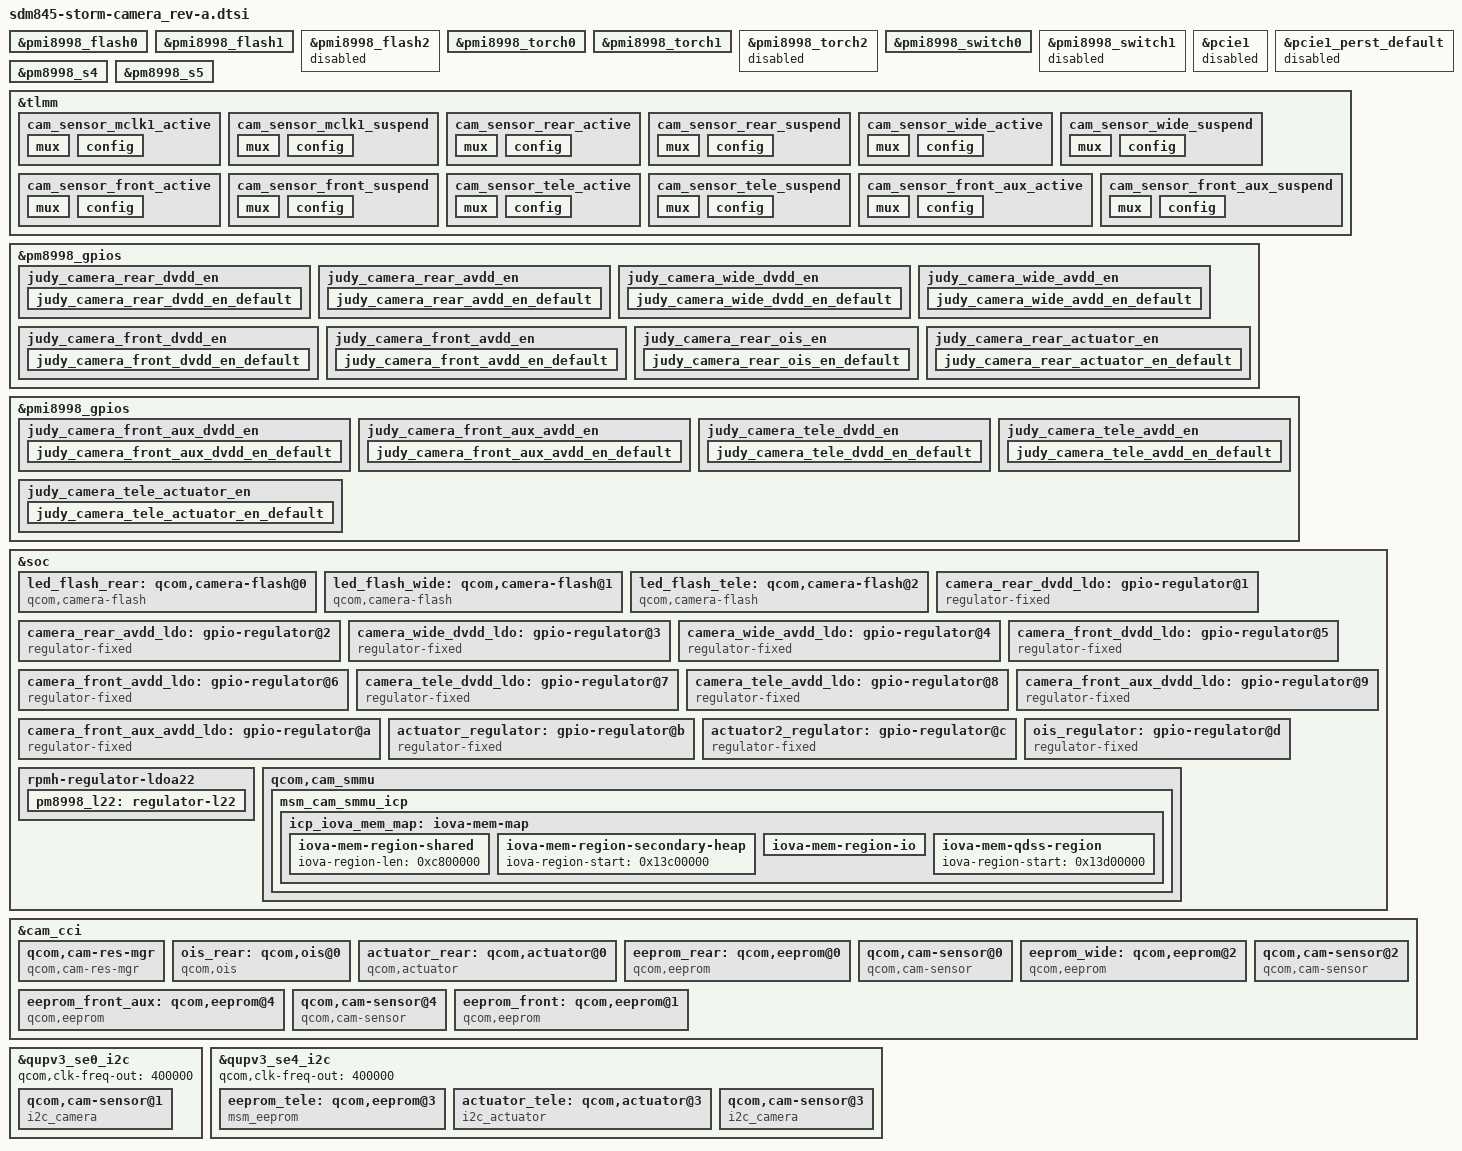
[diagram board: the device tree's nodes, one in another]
/*
 * Copyright (c) 2017 The Linux Foundation. All rights reserved.
 *
 * This program is free software; you can redistribute it and/or modify
 * it under the terms of the GNU General Public License version 2 and
 * only version 2 as published by the Free Software Foundation.
 *
 * This program is distributed in the hope that it will be useful,
 * but WITHOUT ANY WARRANTY; without even the implied warranty of
 * MERCHANTABILITY or FITNESS FOR A PARTICULAR PURPOSE.  See the
 * GNU General Public License for more details.
 */

&pmi8998_flash0 {
	status = "ok";
	qcom,max-current = <850>;
	qcom,current-ma = <850>;
	qcom,duration-ms = <500>;
};

&pmi8998_flash1 {
	status = "ok";
	qcom,max-current = <850>;
	qcom,current-ma = <850>;
	qcom,duration-ms = <500>;
};

&pmi8998_flash2 {
	status = "disabled";
};

&pmi8998_torch0 {
	status = "ok";
	qcom,max-current = <100>;
	qcom,current-ma = <100>;
};

&pmi8998_torch1 {
	status = "ok";
	qcom,max-current = <100>;
	qcom,current-ma = <100>;
};

&pmi8998_torch2 {
	status = "disabled";
};

&pmi8998_switch0 {
	status = "ok";
};

&pmi8998_switch1 {
	status = "disbled";
};

&pcie1 {
    status = "disabled";
};
&pcie1_perst_default {
    status = "disabled";
};

&pm8998_s4 {
	regulator-min-microvolt = <1800000>;
	regulator-max-microvolt = <1800000>;
	qcom,init-voltage = <1800000>;
};

&pm8998_s5 {
	regulator-min-microvolt = <2040000>;
	regulator-max-microvolt = <2040000>;
	qcom,init-voltage = <2040000>;
};

&tlmm{
        cam_sensor_mclk1_active: cam_sensor_mclk1_active {
            /* MCLK1 */
            mux {
                pins = "gpio14";
                function = "cam_mclk";
            };

            config {
                pins = "gpio14";
                bias-disable; /* No PULL */
                drive-strength = <2>; /* 2 MA */
            };
        };

        cam_sensor_mclk1_suspend: cam_sensor_mclk1_suspend {
            /* MCLK1 */
            mux {
                pins = "gpio14";
                function = "cam_mclk";
            };

            config {
                pins = "gpio14";
                bias-pull-down; /* PULL DOWN */
                drive-strength = <2>; /* 2 MA */
            };
        };

	cam_sensor_rear_active: cam_sensor_rear_active {
		/* RESET, AVDD LDO */
		mux {
			pins = "gpio84";
			function = "gpio";
		};

		config {
			pins = "gpio84";
			bias-disable; /* No PULL */
			drive-strength = <2>; /* 2 MA */
		};
	};

	cam_sensor_rear_suspend: cam_sensor_rear_suspend {
		/* RESET, AVDD LDO */
		mux {
			pins = "gpio84";
			function = "gpio";
		};

		config {
			pins = "gpio84";
			bias-pull-down; /* PULL DOWN */
			drive-strength = <2>; /* 2 MA */
			output-low;
		};
	};

	cam_sensor_wide_active: cam_sensor_wide_active {
		/* RESET, AVDD LDO */
		mux {
			pins = "gpio80", "gpio108", "gpio133", "gpio39";
			function = "gpio";
		};

		config {
			pins = "gpio80", "gpio108", "gpio133", "gpio39";
			bias-disable; /* No PULL */
			drive-strength = <2>; /* 2 MA */
		};
	};

	cam_sensor_wide_suspend: cam_sensor_wide_suspend {
		/* RESET, AVDD LDO */
		mux {
			pins = "gpio80", "gpio108", "gpio133", "gpio39";
			function = "gpio";
		};

		config {
			pins = "gpio80", "gpio108", "gpio133", "gpio39";
			bias-pull-down; /* PULL DOWN */
			drive-strength = <2>; /* 2 MA */
			output-low;
		};
	};

	cam_sensor_front_active: cam_sensor_front_active {
		/* RESET, AVDD LDO */
		mux {
			pins = "gpio9", "gpio44", "gpio51";
			function = "gpio";
		};

		config {
			pins = "gpio9", "gpio44", "gpio51";
			bias-disable; /* No PULL */
			drive-strength = <2>; /* 2 MA */
		};
	};

	cam_sensor_front_suspend: cam_sensor_front_suspend {
		/* RESET, AVDD LDO */
		mux {
			pins = "gpio9", "gpio44", "gpio51";
			function = "gpio";
		};

		config {
			pins = "gpio9", "gpio44", "gpio51";
			bias-pull-down; /* PULL DOWN */
			drive-strength = <2>; /* 2 MA */
			output-low;
		};
	};

	cam_sensor_tele_active: cam_sensor_tele_active {
		/* RESET, AVDD LDO */
		mux {
			pins = "gpio35", "gpio44", "gpio51";
			function = "gpio";
		};

		config {
			pins = "gpio35", "gpio44", "gpio51";
			bias-disable; /* No PULL */
			drive-strength = <2>; /* 2 MA */
			output-low;
		};
	};

	cam_sensor_tele_suspend: cam_sensor_tele_suspend {
		/* RESET, AVDD LDO */
		mux {
			pins = "gpio35", "gpio44", "gpio51";
			function = "gpio";
		};

		config {
			pins = "gpio35", "gpio44", "gpio51";
			bias-pull-down; /* PULL DOWN */
			drive-strength = <2>; /* 2 MA */
			output-low;
		};
	};

	cam_sensor_front_aux_active: cam_sensor_front_aux_active {
		/* RESET, AVDD LDO */
		mux {
			pins = "gpio25", "gpio80", "gpio133", "gpio83";
			function = "gpio";
		};

		config {
			pins = "gpio25", "gpio80", "gpio133", "gpio83";
			bias-disable; /* No PULL */
			drive-strength = <2>; /* 2 MA */
			output-low;
		};
	};

	cam_sensor_front_aux_suspend: cam_sensor_front_aux_suspend {
		/* RESET, AVDD LDO */
		mux {
			pins = "gpio25", "gpio80", "gpio133", "gpio83";
			function = "gpio";
		};

		config {
			pins = "gpio25", "gpio80", "gpio133", "gpio83";
			bias-pull-down; /* PULL DOWN */
			drive-strength = <2>; /* 2 MA */
			output-low;
		};
	};
};

&pm8998_gpios {
	judy_camera_rear_dvdd_en {
		judy_camera_rear_dvdd_en_default: judy_camera_rear_dvdd_en_default {
			pins = "gpio19";
			function = "normal";
			power-source = <0>;
			output-high;
		};
	};

	judy_camera_rear_avdd_en {
		judy_camera_rear_avdd_en_default: judy_camera_rear_avdd_en_default {
			pins = "gpio13";
			function = "normal";
			power-source = <0>;
			output-high;
		};
	};

	judy_camera_wide_dvdd_en {
		judy_camera_wide_dvdd_en_default: judy_camera_wide_dvdd_en_default {
			pins = "gpio14";
			function = "normal";
			power-source = <0>;
			output-high;
		};
	};

	judy_camera_wide_avdd_en {
		judy_camera_wide_avdd_en_default: judy_camera_wide_avdd_en_default {
			pins = "gpio16";
			function = "normal";
			power-source = <0>;
			output-high;
		};
	};

	judy_camera_front_dvdd_en {
		judy_camera_front_dvdd_en_default: judy_camera_front_dvdd_en_default {
			pins = "gpio17";
			function = "normal";
			power-source = <0>;
			output-high;
		};
	};

	judy_camera_front_avdd_en {
		judy_camera_front_avdd_en_default: judy_camera_front_avdd_en_default {
			pins = "gpio15";
			function = "normal";
			power-source = <0>;
			output-high;
		};
	};

	judy_camera_rear_ois_en {
		judy_camera_rear_ois_en_default: judy_camera_rear_ois_en_default {
		    /* CAM0_MVDD*/
			pins = "gpio7";
			function = "normal";
			power-source = <0>;
			output-high;
		};
	};

	judy_camera_rear_actuator_en {
		judy_camera_rear_actuator_en_default: judy_camera_rear_actuator_en_default {
		    /* CAM0_AFVDD*/
			pins = "gpio5";
			function = "normal";
			power-source = <0>;
			output-high;
		};
	};

 };

&pmi8998_gpios {
	judy_camera_front_aux_dvdd_en {
		judy_camera_front_aux_dvdd_en_default: judy_camera_front_aux_dvdd_en_default {
			pins = "gpio14";
			function = "normal";
			power-source = <0>;
			output-high;
		};
	};

	judy_camera_front_aux_avdd_en {
		judy_camera_front_aux_avdd_en_default: judy_camera_front_aux_avdd_en_default {
			pins = "gpio12";
			function = "normal";
			power-source = <0>;
			output-high;
		};
	};

	judy_camera_tele_dvdd_en {
		judy_camera_tele_dvdd_en_default: judy_camera_tele_dvdd_en_default {
			pins = "gpio5";
			function = "normal";
			power-source = <0>;
			output-high;
		};
	};

	judy_camera_tele_avdd_en {
		judy_camera_tele_avdd_en_default: judy_camera_tele_avdd_en_default {
			pins = "gpio8";
			function = "normal";
			power-source = <0>;
			output-high;
		};
	};

	judy_camera_tele_actuator_en {
		judy_camera_tele_actuator_en_default: judy_camera_tele_actuator_en_default {
		    /* CAM3_AFVDD*/
			pins = "gpio11";
			function = "normal";
			power-source = <0>;
			output-high;
		};
	};
};

&soc {
	led_flash_rear: qcom,camera-flash@0 {
		cell-index = <0>;
		reg = <0x00 0x00>;
		compatible = "qcom,camera-flash";
		flash-source = <&pmi8998_flash0 &pmi8998_flash1>;
		torch-source = <&pmi8998_torch0 &pmi8998_torch1>;
		switch-source = <&pmi8998_switch0>;
		status = "ok";
	};

	led_flash_wide: qcom,camera-flash@1 {
		cell-index = <1>;
		reg = <0x01 0x00>;
		compatible = "qcom,camera-flash";
		flash-source = <&pmi8998_flash0 &pmi8998_flash1>;
		torch-source = <&pmi8998_torch0 &pmi8998_torch1>;
		switch-source = <&pmi8998_switch0>;
		status = "ok";
	};

	led_flash_tele: qcom,camera-flash@2 {
		cell-index = <2>;
		reg = <0x02 0x00>;
		compatible = "qcom,camera-flash";
		flash-source = <&pmi8998_flash0 &pmi8998_flash1>;
		torch-source = <&pmi8998_torch0 &pmi8998_torch1>;
		switch-source = <&pmi8998_switch0>;
		status = "ok";
	};

	camera_rear_dvdd_ldo: gpio-regulator@1 {
		compatible = "regulator-fixed";
		reg = <0x01 0x00>;
		regulator-name = "camera_rear_dvdd_ldo";
		regulator-min-microvolt = <1050000>;
		regulator-max-microvolt = <1050000>;
		regulator-enable-ramp-delay = <135>;
		enable-active-high;
		gpio = <&pm8998_gpios 19 0>;
		pinctrl-names = "default";
		pinctrl-0 = <&judy_camera_rear_dvdd_en_default>;
		vin-supply = <&pm8998_s4>;
	};

	camera_rear_avdd_ldo: gpio-regulator@2 {
		compatible = "regulator-fixed";
		reg = <0x02 0x00>;
		regulator-name = "camera_rear_avdd_ldo";
		regulator-min-microvolt = <2800000>;
		regulator-max-microvolt = <2800000>;
		regulator-enable-ramp-delay = <135>;
		enable-active-high;
		gpio = <&pm8998_gpios 13 0>;
        pinctrl-names = "default";
        pinctrl-0 = <&judy_camera_rear_avdd_en_default>;
		vin-supply = <&pmi8998_bob>;
	};

	camera_wide_dvdd_ldo: gpio-regulator@3 {
		compatible = "regulator-fixed";
		reg = <0x03 0x00>;
		regulator-name = "camera_wide_dvdd_ldo";
		regulator-min-microvolt = <1050000>;
		regulator-max-microvolt = <1050000>;
		regulator-enable-ramp-delay = <135>;
		enable-active-high;
		gpio = <&pm8998_gpios 14 0>;
		pinctrl-names = "default";
		pinctrl-0 = <&judy_camera_wide_dvdd_en_default>;
		vin-supply = <&pm8998_s4>;
	};

	camera_wide_avdd_ldo: gpio-regulator@4 {
		compatible = "regulator-fixed";
		reg = <0x04 0x00>;
		regulator-name = "camera_wide_avdd_ldo";
		regulator-min-microvolt = <2800000>;
		regulator-max-microvolt = <2800000>;
		regulator-enable-ramp-delay = <135>;
		enable-active-high;
		gpio = <&pm8998_gpios 16 0>;
        pinctrl-names = "default";
        pinctrl-0 = <&judy_camera_wide_avdd_en_default>;
		vin-supply = <&pmi8998_bob>;
	};

	camera_front_dvdd_ldo: gpio-regulator@5 {
		compatible = "regulator-fixed";
		reg = <0x05 0x00>;
		regulator-name = "camera_front_dvdd_ldo";
		regulator-min-microvolt = <1200000>;
		regulator-max-microvolt = <1200000>;
		regulator-enable-ramp-delay = <135>;
		enable-active-high;
		gpio = <&pm8998_gpios 17 0>;
		pinctrl-names = "default";
		pinctrl-0 = <&judy_camera_front_dvdd_en_default>;
		vin-supply = <&pm8998_s4>;
	};

	camera_front_avdd_ldo: gpio-regulator@6 {
		compatible = "regulator-fixed";
		reg = <0x06 0x00>;
		regulator-name = "camera_front_avdd_ldo";
		regulator-min-microvolt = <2800000>;
		regulator-max-microvolt = <2800000>;
		regulator-enable-ramp-delay = <135>;
		enable-active-high;
		gpio = <&pm8998_gpios 15 0>;
		pinctrl-names = "default";
		pinctrl-0 = <&judy_camera_front_avdd_en_default>;
		vin-supply = <&pmi8998_bob>;
	};

	camera_tele_dvdd_ldo: gpio-regulator@7 {
		compatible = "regulator-fixed";
		reg = <0x07 0x00>;
		regulator-name = "camera_tele_dvdd_ldo";
		regulator-min-microvolt = <1050000>;
		regulator-max-microvolt = <1050000>;
		regulator-enable-ramp-delay = <135>;
		enable-active-high;
		gpio = <&pmi8998_gpios 5 0>;
		pinctrl-names = "default";
		pinctrl-0 = <&judy_camera_tele_dvdd_en_default>;
		vin-supply = <&pm8998_s4>;
	};

	camera_tele_avdd_ldo: gpio-regulator@8 {
		compatible = "regulator-fixed";
		reg = <0x08 0x00>;
		regulator-name = "camera_tele_avdd_ldo";
		regulator-min-microvolt = <2800000>;
		regulator-max-microvolt = <2800000>;
		regulator-enable-ramp-delay = <135>;
		enable-active-high;
		gpio = <&pmi8998_gpios 8 0>;
		pinctrl-names = "default";
		pinctrl-0 = <&judy_camera_tele_avdd_en_default>;
		vin-supply = <&pmi8998_bob>;
	};

	camera_front_aux_dvdd_ldo: gpio-regulator@9 {
		compatible = "regulator-fixed";
		reg = <0x09 0x00>;
		regulator-name = "camera_front_aux_dvdd_ldo";
		regulator-min-microvolt = <1200000>;
		regulator-max-microvolt = <1200000>;
		regulator-enable-ramp-delay = <135>;
		enable-active-high;
		gpio = <&pmi8998_gpios 14 0>;
		pinctrl-names = "default";
		pinctrl-0 = <&judy_camera_front_aux_dvdd_en_default>;
		vin-supply = <&pm8998_s4>;
	};
	camera_front_aux_avdd_ldo: gpio-regulator@a {
		compatible = "regulator-fixed";
		reg = <0x0a 0x00>;
		regulator-name = "camera_front_aux_avdd_ldo";
		regulator-min-microvolt = <2800000>;
		regulator-max-microvolt = <2800000>;
		regulator-enable-ramp-delay = <135>;
		enable-active-high;
		gpio = <&pmi8998_gpios 12 0>;
		pinctrl-names = "default";
		pinctrl-0 = <&judy_camera_front_aux_avdd_en_default>;
		vin-supply = <&pmi8998_bob>;
	};

	actuator_regulator: gpio-regulator@b {
		compatible = "regulator-fixed";
		reg = <0x0b 0x00>;
		regulator-name = "actuator_regulator";
		regulator-min-microvolt = <3000000>;
		regulator-max-microvolt = <3000000>;
		regulator-enable-ramp-delay = <100>;
		enable-active-high;
		gpio = <&pm8998_gpios 5 0>;
		pinctrl-names = "default";
		pinctrl-0 = <&judy_camera_rear_actuator_en_default>;
		vin-supply = <&pmi8998_bob>;
	};

	actuator2_regulator: gpio-regulator@c {
		compatible = "regulator-fixed";
		reg = <0x0c 0x00>;
		regulator-name = "actuator2_regulator";
		regulator-min-microvolt = <3000000>;
		regulator-max-microvolt = <3000000>;
		regulator-enable-ramp-delay = <100>;
		enable-active-high;
		gpio = <&pmi8998_gpios 11 0>;
		pinctrl-names = "default";
		pinctrl-0 = <&judy_camera_tele_actuator_en_default>;
		vin-supply = <&pmi8998_bob>;
	};

	ois_regulator: gpio-regulator@d {
		compatible = "regulator-fixed";
		reg = <0x0d 0x00>;
		regulator-name = "ois_regulator";
		regulator-min-microvolt = <3000000>;
		regulator-max-microvolt = <3000000>;
		regulator-enable-ramp-delay = <100>;
		enable-active-high;
		gpio = <&pm8998_gpios 7 0>;
		pinctrl-names = "default";
		pinctrl-0 = <&judy_camera_rear_ois_en_default>;
		vin-supply = <&pmi8998_bob>;
	};

	rpmh-regulator-ldoa22 {
		pm8998_l22: regulator-l22 {
			regulator-min-microvolt = <1800000>;
			regulator-max-microvolt = <1800000>;
			qcom,init-voltage = <1800000>;
		};
	};

	qcom,cam_smmu {
		msm_cam_smmu_icp {
			icp_iova_mem_map: iova-mem-map {
				iova-mem-region-shared {
					/* Shared region is 100MB long ,LGE_CHANGE, 100MB -> 200MB*/
					iova-region-len = <0xc800000>;
					status = "ok";
				};

				iova-mem-region-secondary-heap {
					/* Secondary heap region is 1MB long */
					iova-region-start = <0x13c00000>;
					status = "ok";
				};

				iova-mem-region-io {
					/* IO region is approximately 3 GB */
					iova-region-start = <0x13e00000>;
					iova-region-len = <0xcc100000>;
					status = "ok";
				};

				iova-mem-qdss-region {
					/* qdss region is approximately 1MB */
					iova-region-start = <0x13d00000>;
					status = "ok";
				};
			};
		};
	};
};

&cam_cci {
    qcom,cam-res-mgr {
		compatible = "qcom,cam-res-mgr";
		status = "ok";
	};

	ois_rear: qcom,ois@0 {
		cell-index = <0>;
		reg = <0x0>;
		compatible = "qcom,ois";
		cci-master = <0>;
		cam_vaf-supply = <&actuator_regulator>;
		cam_v_custom1-supply = <&ois_regulator>;
		regulator-names = "cam_vaf","cam_v_custom1";
		rgltr-cntrl-support;
		rgltr-min-voltage = <3000000 3000000>;
		rgltr-max-voltage = <3000000 3000000>;
		rgltr-load-current = <0 0>;
		status = "ok";
	};

	actuator_rear: qcom,actuator@0 {
		cell-index = <0>;
		reg = <0x0>;
		compatible = "qcom,actuator";
		cci-master = <0>;
		cam_vaf-supply = <&actuator_regulator>;
		rgltr-cntrl-support;
		regulator-names = "cam_vaf";
		rgltr-min-voltage = <3000000>;
		rgltr-max-voltage = <3000000>;
		rgltr-load-current = <0>;
	};

	eeprom_rear: qcom,eeprom@0 {
		cell-index = <0>;
		reg = <0>;
		compatible = "qcom,eeprom";
		cam_vio-supply = <&pm8998_lvs1>;
		cam_vana-supply = <&camera_rear_avdd_ldo>;
		cam_vdig-supply = <&camera_rear_dvdd_ldo>;
		cam_v_custom1-supply = <&pm8998_s5>;
		cam_clk-supply = <&titan_top_gdsc>;
		regulator-names = "cam_vio", "cam_vana", "cam_vdig", "cam_clk", "cam_v_custom1";
		rgltr-cntrl-support;
		rgltr-min-voltage = <0 2800000 1050000 0 2040000>;
		rgltr-max-voltage = <0 2800000 1050000 0 2040000>;
		rgltr-load-current = <0 2800000 1050000 0 2040000>;
		gpio-no-mux = <0>;
		pinctrl-names = "cam_default", "cam_suspend";
		pinctrl-0 = <&cam_sensor_mclk0_active
				&cam_sensor_rear_active>;
		pinctrl-1 = <&cam_sensor_mclk0_suspend
				&cam_sensor_rear_suspend>;
		gpios = <&tlmm 13 0>,
			<&tlmm 84 0>;
		gpio-reset = <1>;
		gpio-req-tbl-num = <0 1>;
		gpio-req-tbl-flags = <1 0>;
		gpio-req-tbl-label = "CAMIF_MCLK0",
					"CAM_RESET0";
		sensor-position = <0>;
		sensor-mode = <0>;
		cci-master = <0>;
		status = "ok";
		clocks = <&clock_camcc CAM_CC_MCLK0_CLK>;
		clock-names = "cam_clk";
		clock-cntl-level = "turbo";
		clock-rates = <24000000>;
	};

	qcom,cam-sensor@0 {
		cell-index = <0>;
		compatible = "qcom,cam-sensor";
		reg = <0x0>;
		csiphy-sd-index = <0>;
		sensor-position-roll = <90>;
		sensor-position-pitch = <0>;
		sensor-position-yaw = <180>;
		ois-src = <&ois_rear>;
		actuator-src = <&actuator_rear>;
		eeprom-src = <&eeprom_rear>;
		led-flash-src = <&led_flash_rear>;
		cam_vio-supply = <&pm8998_lvs1>;
		cam_vana-supply = <&camera_rear_avdd_ldo>;
		cam_vdig-supply = <&camera_rear_dvdd_ldo>;
        	cam_v_custom1-supply = <&pm8998_s5>;
		cam_clk-supply = <&titan_top_gdsc>;
		regulator-names = "cam_vio", "cam_vana", "cam_vdig", "cam_clk", "cam_v_custom1";
		rgltr-cntrl-support;
		rgltr-min-voltage = <0 2800000 1050000 0 2040000>;
		rgltr-max-voltage = <0 2800000 1050000 0 2040000>;
		rgltr-load-current = <0 2800000 1050000 0 2040000>;
		gpio-no-mux = <0>;
		pinctrl-names = "cam_default", "cam_suspend";
		pinctrl-0 = <&cam_sensor_mclk0_active
				&cam_sensor_rear_active>;
		pinctrl-1 = <&cam_sensor_mclk0_suspend
				&cam_sensor_rear_suspend>;
		gpios = <&tlmm 13 0>,
			<&tlmm 84 0>;
		gpio-reset = <1>;
		gpio-req-tbl-num = <0 1>;
		gpio-req-tbl-flags = <1 0>;
		gpio-req-tbl-label = "CAMIF_MCLK0",
					"CAM_RESET0";
		sensor-mode = <0>;
		cci-master = <0>;
		status = "ok";
		clocks = <&clock_camcc CAM_CC_MCLK0_CLK>;
		clock-names = "cam_clk";
		clock-cntl-level = "turbo";
		clock-rates = <24000000>;
	};

	eeprom_wide: qcom,eeprom@2 {
		cell-index = <2>;
		reg = <0x2>;
		compatible = "qcom,eeprom";
		cam_vio-supply = <&pm8998_l14>;
		cam_vana-supply = <&camera_wide_avdd_ldo>;
		cam_vdig-supply = <&camera_wide_dvdd_ldo>;
                cam_v_custom1-supply = <&pm8998_s4>;
		cam_clk-supply = <&titan_top_gdsc>;
		regulator-names = "cam_vio", "cam_vana", "cam_vdig", "cam_clk", "cam_v_custom1";
		rgltr-cntrl-support;
		rgltr-min-voltage = <0 2800000 1050000 0 1800000>;
		rgltr-max-voltage = <0 2800000 1050000 0 1800000>;
		rgltr-load-current = <0 2800000 1050000 0 1800000>;
		gpio-no-mux = <0>;
		pinctrl-names = "cam_default", "cam_suspend";
		pinctrl-0 = <&cam_sensor_mclk1_active
				&cam_sensor_wide_active>;
		pinctrl-1 = <&cam_sensor_mclk1_suspend
				&cam_sensor_wide_suspend>;
		gpios = <&tlmm 14 0>,
			<&tlmm 108 0>,
			<&tlmm 80 0>,
			<&tlmm 133 0>,
			<&tlmm 39 0>;
		gpio-reset = <1>;
		gpio-custom1 = <2>;
		gpio-custom2 = <3>;
		gpio-standby = <4>;
		gpio-req-tbl-num = <0 1 2 3 4>;
		gpio-req-tbl-flags = <1 0 0 0 0>;
		gpio-req-tbl-label = "CAMIF_MCLK1",
					"CAM_RESET1",
					"CAM1_SW_OE",
					"CAM1_SW_SEL",
					"CAM1_MCLK_EN";
		sensor-mode = <0>;
		cci-master = <1>;
		status = "ok";
		clocks = <&clock_camcc CAM_CC_MCLK1_CLK>;
		clock-names = "cam_clk";
		clock-cntl-level = "turbo";
		clock-rates = <24000000>;
	};

	qcom,cam-sensor@2 {
		cell-index = <2>;
		compatible = "qcom,cam-sensor";
		reg = <0x2>;
		csiphy-sd-index = <1>;
		sensor-position-roll = <90>;
		sensor-position-pitch = <0>;
		sensor-position-yaw = <180>;
		led-flash-src = <&led_flash_wide>;
		eeprom-src = <&eeprom_wide>;
		cam_vio-supply = <&pm8998_l14>;
		cam_vana-supply = <&camera_wide_avdd_ldo>;
		cam_vdig-supply = <&camera_wide_dvdd_ldo>;
		cam_v_custom1-supply = <&pm8998_s4>;
		cam_clk-supply = <&titan_top_gdsc>;
		regulator-names = "cam_vio", "cam_vana", "cam_vdig", "cam_clk", "cam_v_custom1";
		rgltr-cntrl-support;
		rgltr-min-voltage = <0 2800000 1050000 0 1800000>;
		rgltr-max-voltage = <0 2800000 1050000 0 1800000>;
		rgltr-load-current = <0 2800000 1050000 0 1800000>;
		gpio-no-mux = <0>;
		pinctrl-names = "cam_default", "cam_suspend";
		pinctrl-0 = <&cam_sensor_mclk1_active
				&cam_sensor_wide_active>;
		pinctrl-1 = <&cam_sensor_mclk1_suspend
				&cam_sensor_wide_suspend>;
		gpios = <&tlmm 14 0>,
			<&tlmm 108 0>,
			<&tlmm 80 0>,
			<&tlmm 133 0>,
			<&tlmm 39 0>;
		gpio-reset = <1>;
		gpio-custom1 = <2>;
		gpio-custom2 = <3>;
		gpio-standby = <4>;
		gpio-req-tbl-num = <0 1 2 3 4>;
		gpio-req-tbl-flags = <1 0 0 0 0>;
		gpio-req-tbl-label = "CAMIF_MCLK1",
					"CAM_RESET1",
					"CAM1_SW_OE",
					"CAM1_SW_SEL",
					"CAM1_MCLK_EN";
		sensor-mode = <0>;
		cci-master = <1>;
		status = "ok";
		clocks = <&clock_camcc CAM_CC_MCLK1_CLK>;
		clock-names = "cam_clk";
		clock-cntl-level = "turbo";
		clock-rates = <24000000>;
	};

	eeprom_front_aux: qcom,eeprom@4 {
		cell-index = <4>;
		reg = <0x4>;
		compatible = "qcom,eeprom";
		cam_vio-supply = <&pm8998_l14>;
		cam_vana-supply = <&camera_front_aux_avdd_ldo>;
		cam_vdig-supply = <&camera_front_aux_dvdd_ldo>;
		cam_v_custom1-supply = <&pm8998_s4>;
		cam_clk-supply = <&titan_top_gdsc>;
		regulator-names = "cam_vio", "cam_vana", "cam_vdig", "cam_clk", "cam_v_custom1";
		rgltr-cntrl-support;
		rgltr-min-voltage = <0 2800000 1200000 0 1800000>;
		rgltr-max-voltage = <0 2800000 1200000 0 1800000>;
		rgltr-load-current = <0 2800000 1200000 0 1800000>;
		gpio-no-mux = <0>;
		pinctrl-names = "cam_default", "cam_suspend";
		pinctrl-0 = <&cam_sensor_mclk1_active
				&cam_sensor_front_aux_active>;
		pinctrl-1 = <&cam_sensor_mclk1_suspend
				&cam_sensor_front_aux_suspend>;
		gpios = <&tlmm 14 0>,
			<&tlmm 25 0>,
			<&tlmm 80 0>,
			<&tlmm 133 0>,
			<&tlmm 83 0>;
		gpio-reset = <1>;
		gpio-custom1 = <2>;
		gpio-custom2 = <3>;
		gpio-standby = <4>;
		gpio-req-tbl-num = <0 1 2 3 4>;
		gpio-req-tbl-flags = <1 0 0 0 0>;
		gpio-req-tbl-label = "CAMIF_MCLK1",
					"CAM_RESET1",
					"CAM1_SW_OE",
					"CAM1_SW_SEL",
					"CAM1_MCLK_EN";
		sensor-mode = <1>;
		cci-master = <1>;
		status = "ok";
		clocks = <&clock_camcc CAM_CC_MCLK1_CLK>;
		clock-names = "cam_clk";
		clock-cntl-level = "turbo";
		clock-rates = <24000000>;
	};

	qcom,cam-sensor@4 {
		cell-index = <4>;
		compatible = "qcom,cam-sensor";
		reg = <0x4>;
		csiphy-sd-index = <1>;
		sensor-position-roll = <270>;
		sensor-position-pitch = <0>;
		sensor-position-yaw = <0>;
		eeprom-src = <&eeprom_front_aux>;
		cam_vio-supply = <&pm8998_l14>;
		cam_vana-supply = <&camera_front_aux_avdd_ldo>;
		cam_vdig-supply = <&camera_front_aux_dvdd_ldo>;
		cam_v_custom1-supply = <&pm8998_s4>;
		cam_clk-supply = <&titan_top_gdsc>;
		regulator-names = "cam_vio", "cam_vana", "cam_vdig", "cam_clk", "cam_v_custom1";
		rgltr-cntrl-support;
		rgltr-min-voltage = <0 2800000 1200000 0 1800000>;
		rgltr-max-voltage = <0 2800000 1200000 0 1800000>;
		rgltr-load-current = <0 2800000 1200000 0 1800000>;
		gpio-no-mux = <0>;
		pinctrl-names = "cam_default", "cam_suspend";
		pinctrl-0 = <&cam_sensor_mclk1_active
				&cam_sensor_front_aux_active>;
		pinctrl-1 = <&cam_sensor_mclk1_suspend
				&cam_sensor_front_aux_suspend>;
		gpios = <&tlmm 14 0>,
			<&tlmm 25 0>,
			<&tlmm 80 0>,
			<&tlmm 133 0>,
			<&tlmm 83 0>;
		gpio-reset = <1>;
		gpio-custom1 = <2>;
		gpio-custom2 = <3>;
		gpio-standby = <4>;
		gpio-req-tbl-num = <0 1 2 3 4>;
		gpio-req-tbl-flags = <1 0 0 0 0>;
		gpio-req-tbl-label = "CAMIF_MCLK1",
					"CAM_RESET1",
					"CAM1_SW_OE",
					"CAM1_SW_SEL",
					"CAM1_MCLK_EN";
		sensor-mode = <1>;
		cci-master = <1>;
		status = "ok";
		clocks = <&clock_camcc CAM_CC_MCLK1_CLK>;
		clock-names = "cam_clk";
		clock-cntl-level = "turbo";
		clock-rates = <24000000>;
	};

	eeprom_front: qcom,eeprom@1{
		cell-index = <1>;
		compatible = "qcom,eeprom";
		reg = <0x1>;
		cam_vio-supply = <&pm8998_l14>;
		cam_vana-supply = <&camera_front_aux_avdd_ldo>;
		cam_vdig-supply = <&camera_front_aux_dvdd_ldo>;
        cam_v_custom1-supply = <&pm8998_s4>;
		cam_clk-supply = <&titan_top_gdsc>;
		regulator-names = "cam_vio", "cam_vana", "cam_vdig", "cam_clk", "cam_v_custom1";
		rgltr-cntrl-support;
		rgltr-min-voltage = <0 2800000 1200000 0 1800000>;
		rgltr-max-voltage = <0 2800000 1200000 0 1800000>;
		rgltr-load-current = <0 2800000 1200000 0 1800000>;
		gpio-no-mux = <0>;
		pinctrl-names = "cam_default", "cam_suspend";
		pinctrl-0 = <&cam_sensor_mclk1_active
				&cam_sensor_front_aux_active>;
		pinctrl-1 = <&cam_sensor_mclk1_suspend
				&cam_sensor_front_aux_suspend>;
		gpios = <&tlmm 14 0>,
			<&tlmm 25 0>,
			<&tlmm 80 0>,
			<&tlmm 133 0>,
			<&tlmm 83 0>;
		gpio-reset = <1>;
		gpio-custom1 = <2>;
		gpio-custom2 = <3>;
		gpio-standby = <4>;
		gpio-req-tbl-num = <0 1 2 3 4>;
		gpio-req-tbl-flags = <1 0 0 0 0>;
		gpio-req-tbl-label = "CAMIF_MCLK1",
					"CAM_RESET1",
					"CAM1_SW_OE",
					"CAM1_SW_SEL",
					"CAM1_MCLK_EN";
		sensor-mode = <1>;
		cci-master = <1>;
		status = "ok";
		clocks = <&clock_camcc CAM_CC_MCLK1_CLK>;
		clock-names = "cam_clk";
		clock-cntl-level = "turbo";
		clock-rates = <24000000>;
	};
};

&qupv3_se0_i2c {
		status = "ok";
        qcom,clk-freq-out = <400000>;

	qcom,cam-sensor@1 {
		cell-index = <1>;
		compatible = "i2c_camera";
		reg = <0x42>;
		csiphy-sd-index = <2>;
		sensor-position-roll = <270>;
		sensor-position-pitch = <0>;
		sensor-position-yaw = <0>;
		eeprom-src = <&eeprom_front>;
		cam_vio-supply = <&pm8998_l22>;
		cam_vana-supply = <&camera_front_avdd_ldo>;
		cam_vdig-supply = <&camera_front_dvdd_ldo>;
		cam_clk-supply = <&titan_top_gdsc>;
		cam_v_custom1-supply = <&pm8998_s4>;
		regulator-names = "cam_vio", "cam_vana", "cam_vdig", "cam_clk", "cam_v_custom1";
		rgltr-cntrl-support;
		rgltr-min-voltage = <1800000 2800000 1200000 0 1800000>;
		rgltr-max-voltage = <1800000 2800000 1200000 0 1800000>;
		rgltr-load-current = <1800000 2800000 1200000 0 1800000>;
		gpio-no-mux = <0>;
		pinctrl-names = "cam_default", "cam_suspend";
		pinctrl-0 = <&cam_sensor_mclk2_active
				&cam_sensor_front_active>;
		pinctrl-1 = <&cam_sensor_mclk2_suspend
				&cam_sensor_front_suspend>;
		gpios = <&tlmm 15 0>,
			<&tlmm 9 0>,
			<&tlmm 44 0>,
			<&tlmm 51 0>;
		gpio-reset = <1>;
		gpio-custom1 = <2>;
		gpio-custom2 = <3>;
		gpio-req-tbl-num = <0 1 2 3>;
		gpio-req-tbl-flags = <1 0 0 0>;
		gpio-req-tbl-label = "CAMIF_MCLK2",
					"CAM_RESET2",
					"CAM2_SW_OE",
					"CAM2_SW_SEL";
		sensor-mode = <1>;
		status = "ok";
		clocks = <&clock_camcc CAM_CC_MCLK2_CLK>;
		clock-names = "cam_clk";
		clock-cntl-level = "turbo";
		clock-rates = <24000000>;
	};
};


&qupv3_se4_i2c {
        status = "ok";
        qcom,clk-freq-out = <400000>;

	eeprom_tele: qcom,eeprom@3{
	    cell-index = <3>;
	    compatible = "msm_eeprom";
	    reg = <0x50>; // 7bit slave address
		cam_vio-supply = <&pm8998_l22>;
		cam_vana-supply = <&camera_tele_avdd_ldo>;
		cam_vdig-supply = <&camera_tele_dvdd_ldo>;
                cam_v_custom1-supply = <&pm8998_s4>;
		cam_clk-supply = <&titan_top_gdsc>;
		regulator-names = "cam_vio", "cam_vana", "cam_vdig", "cam_clk", "cam_v_custom1";
		rgltr-cntrl-support;
		rgltr-min-voltage = <0 2800000 1050000 0 1800000>;
		rgltr-max-voltage = <0 2800000 1050000 0 1800000>;
		rgltr-load-current = <0 2800000 1050000 0 1800000>;
		gpio-no-mux = <0>;
		pinctrl-names = "cam_default", "cam_suspend";
		pinctrl-0 = <&cam_sensor_mclk3_active
				&cam_sensor_tele_active>;
		pinctrl-1 = <&cam_sensor_mclk3_suspend
				&cam_sensor_tele_suspend>;
		gpios = <&tlmm 16 0>,
			<&tlmm 35 0>,
			<&tlmm 44 0>,
			<&tlmm 51 0>;
		gpio-reset = <1>;
		gpio-custom1 = <2>;
		gpio-custom2 = <3>;
		gpio-req-tbl-num = <0 1 2 3>;
		gpio-req-tbl-flags = <1 0 0 0>;
		gpio-req-tbl-label = "CAMIF_MCLK3",
					"CAM_RESET3",
					"CAM3_SW_OE",
					"CAM3_SW_SEL";
		sensor-mode = <0>;
		status = "ok";
		clocks = <&clock_camcc CAM_CC_MCLK3_CLK>;
		clock-names = "cam_clk";
		clock-cntl-level = "turbo";
		clock-rates = <24000000>;
	};

	actuator_tele: qcom,actuator@3 {
		cell-index = <3>;
		reg = <0x72>;
		compatible = "i2c_actuator";
		cam_vaf-supply = <&actuator2_regulator>;
		rgltr-cntrl-support;
		regulator-names = "cam_vaf";
		rgltr-min-voltage = <3000000>;
		rgltr-max-voltage = <3000000>;
		rgltr-load-current = <0>;
		status = "ok";
	};

	qcom,cam-sensor@3 {
		cell-index = <3>;
		compatible = "i2c_camera";
		reg = <0x5A>;
		csiphy-sd-index = <2>;
		sensor-position-roll = <90>;
		sensor-position-pitch = <0>;
		sensor-position-yaw = <180>;
		actuator-src = <&actuator_tele>;
		eeprom-src = <&eeprom_tele>;
		led-flash-src = <&led_flash_tele>;
		cam_vio-supply = <&pm8998_l22>;
		cam_vana-supply = <&camera_tele_avdd_ldo>;
		cam_vdig-supply = <&camera_tele_dvdd_ldo>;
                cam_v_custom1-supply = <&pm8998_s4>;
		cam_clk-supply = <&titan_top_gdsc>;
		regulator-names = "cam_vio", "cam_vana", "cam_vdig", "cam_clk", "cam_v_custom1";
		rgltr-cntrl-support;
		rgltr-min-voltage = <0 2800000 1050000 0 1800000>;
		rgltr-max-voltage = <0 2800000 1050000 0 1800000>;
		rgltr-load-current = <0 2800000 1050000 0 1800000>;
		gpio-no-mux = <0>;
		pinctrl-names = "cam_default", "cam_suspend";
		pinctrl-0 = <&cam_sensor_mclk3_active
				&cam_sensor_tele_active>;
		pinctrl-1 = <&cam_sensor_mclk3_suspend
				&cam_sensor_tele_suspend>;
		gpios = <&tlmm 16 0>,
			<&tlmm 35 0>,
			<&tlmm 44 0>,
			<&tlmm 51 0>;
		gpio-reset = <1>;
        	gpio-custom1 = <2>;
		gpio-custom2 = <3>;
		gpio-req-tbl-num = <0 1 2 3>;
		gpio-req-tbl-flags = <1 0 0 0>;
		gpio-req-tbl-label = "CAMIF_MCLK3",
					"CAM_RESET3",
					"CAM3_SW_OE",
					"CAM3_SW_SEL";
		sensor-mode = <0>;
		status = "ok";
		clocks = <&clock_camcc CAM_CC_MCLK3_CLK>;
		clock-names = "cam_clk";
		clock-cntl-level = "turbo";
		clock-rates = <24000000>;
	};
};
